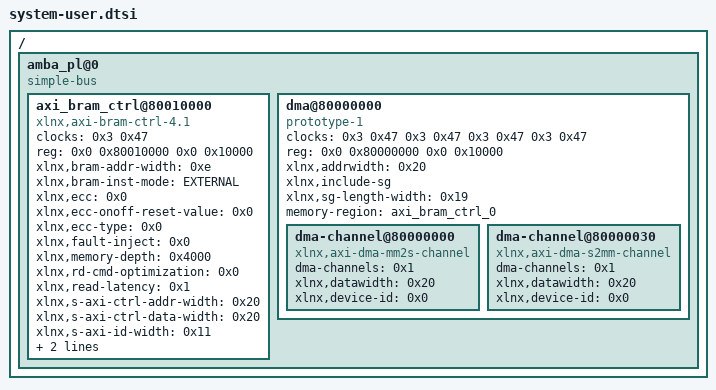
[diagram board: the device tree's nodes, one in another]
/include/ "system-conf.dtsi"
/ {
   	amba_pl@0 {
		#address-cells = <0x2>;
		#size-cells = <0x2>;
		compatible = "simple-bus";
		ranges;
		phandle = <0xa1>;

		axi_bram_ctrl@80010000 {
			clock-names = "s_axi_aclk";
			clocks = <0x3 0x47>;
			compatible = "xlnx,axi-bram-ctrl-4.1";
			reg = <0x0 0x80010000 0x0 0x10000>;
			xlnx,bram-addr-width = <0xe>;
			xlnx,bram-inst-mode = "EXTERNAL";
			xlnx,ecc = <0x0>;
			xlnx,ecc-onoff-reset-value = <0x0>;
			xlnx,ecc-type = <0x0>;
			xlnx,fault-inject = <0x0>;
			xlnx,memory-depth = <0x4000>;
			xlnx,rd-cmd-optimization = <0x0>;
			xlnx,read-latency = <0x1>;
			xlnx,s-axi-ctrl-addr-width = <0x20>;
			xlnx,s-axi-ctrl-data-width = <0x20>;
			xlnx,s-axi-id-width = <0x11>;
			xlnx,s-axi-supports-narrow-burst = <0x1>;
			xlnx,single-port-bram = <0x1>;
			phandle = <0xa2>; 

		};

		dma@80000000 {
			#dma-cells = <0x1>;
			clock-names = "s_axi_lite_aclk", "m_axi_sg_aclk", "m_axi_mm2s_aclk", "m_axi_s2mm_aclk";
			clocks = <0x3 0x47 0x3 0x47 0x3 0x47 0x3 0x47>;
			compatible = "prototype-1";
			reg = <0x0 0x80000000 0x0 0x10000>;
			xlnx,addrwidth = <0x20>;
			xlnx,include-sg;
			xlnx,sg-length-width = <0x19>;
			phandle = <0xa3>;
			memory-region = <&axi_bram_ctrl_0>;
			dma-channel@80000000 {
				compatible = "xlnx,axi-dma-mm2s-channel";
				dma-channels = <0x1>;
				xlnx,datawidth = <0x20>;
				xlnx,device-id = <0x0>;
			};

			dma-channel@80000030 {
				compatible = "xlnx,axi-dma-s2mm-channel";
				dma-channels = <0x1>;
				xlnx,datawidth = <0x20>;
				xlnx,device-id = <0x0>;
			};
		};
};

};
